# STM32N647xx register map
File version: 1.0
Registers are 32-bit, read-write, reset 0x0 unless marked. A register's access mark holds for its fields unless they carry their own. Offsets are from the block's base; [hi:lo] are bit positions; 'fields as' and 'values as' point back to an identical list.

## DTS — DTS Controller
Base 0x4600A000
0x10 PVTREG_LOCKR — DTS PVT Register Lock Register
  [31:0] LOCK — PVT software lock
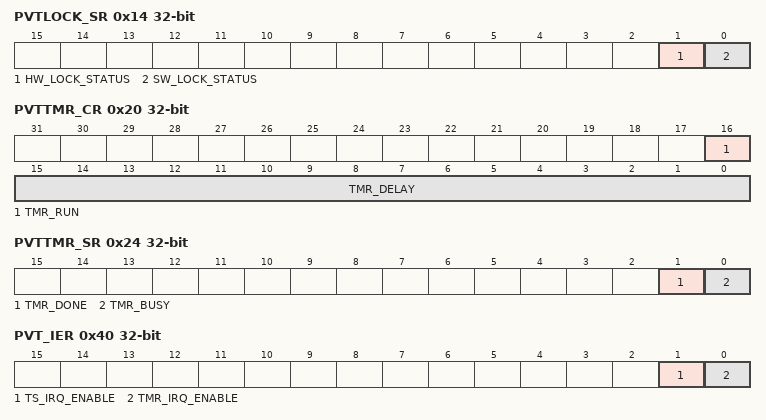
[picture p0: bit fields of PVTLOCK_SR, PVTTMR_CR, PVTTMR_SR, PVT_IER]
0x14 PVTLOCK_SR — DTS PVT Lock Status Register
  [1] HW_LOCK_STATUS — Hardware lock status
  [0] SW_LOCK_STATUS — Software lock status
0x20 PVTTMR_CR — DTS PVT Timer Control Register
  [16] TMR_RUN — Enable
  [15:0] TMR_DELAY — Timer delay
0x24 PVTTMR_SR — DTS PVT Timer Status Register
  [1] TMR_DONE — Cnt delay timeout
  [0] TMR_BUSY — Counter busy flag
0x40 PVT_IER — DTS PVT IRQ Enable Register
  [1] TS_IRQ_ENABLE
  [0] TMR_IRQ_ENABLE — Timer IRQ enable
0x50 PVTIRQTRMASKR — DTS PVT IRQ Timer Mask Register
  [0] TMR_IRQ_MASK — Timer IRQ mask
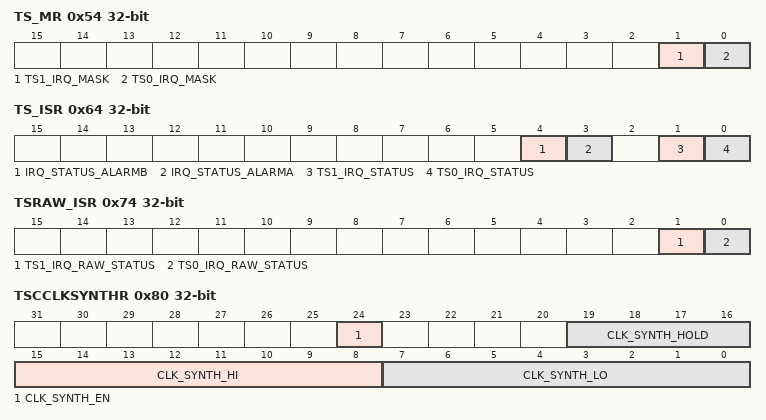
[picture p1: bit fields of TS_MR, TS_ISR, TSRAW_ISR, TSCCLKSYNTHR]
0x54 TS_MR — DTS PVT IRQ TS Mask Register
  [1] TS1_IRQ_MASK, [0] TS0_IRQ_MASK
0x60 PVTTR_SR — DTS PVT IRQ Timer Status Register
  [0] TMR_IRQ_STATUS — Timer IRQ status after masking
0x64 TS_ISR — DTS PVT IRQ TS Status Register
  [4] IRQ_STATUS_ALARMB — TS Alarm B IRQ status
  [3] IRQ_STATUS_ALARMA — TS Alarm A IRQ status
  [1] TS1_IRQ_STATUS — TS1 IRQ status after masking
  [0] TS0_IRQ_STATUS — TS0 IRQ status after masking
0x70 PVTTMRRAW_ISR — DTS PVT IRQ Timer Raw Status Register
  [0] TMR_IRQ_RAW_STATUS — Timer IRQ status before masking
0x74 TSRAW_ISR — DTS PVT IRQ TS Raw Status Register
  [1] TS1_IRQ_RAW_STATUS — TS1 IRQ status before masking
  [0] TS0_IRQ_RAW_STATUS — TS0 IRQ status before masking
0x80 TSCCLKSYNTHR — DTS TSC Clock Synthesizer Register
  [24] CLK_SYNTH_EN — Synthesized enable
  [19:16] CLK_SYNTH_HOLD — Hold input or output delay
  [15:8] CLK_SYNTH_HI — Synthesized clk_ts ghigh period
  [7:0] CLK_SYNTH_LO — Synthesized clk_ts low period
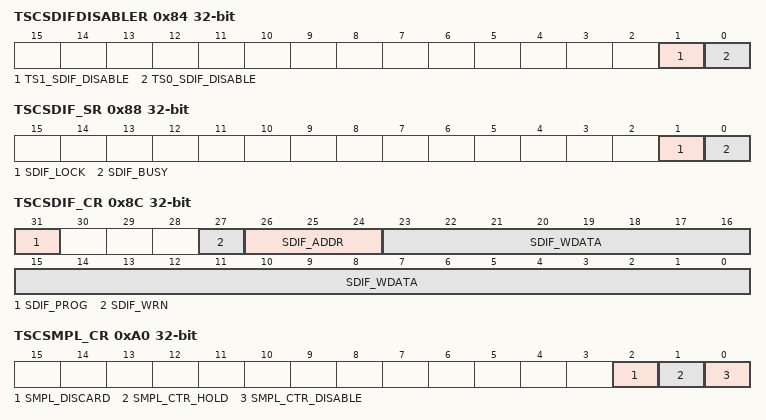
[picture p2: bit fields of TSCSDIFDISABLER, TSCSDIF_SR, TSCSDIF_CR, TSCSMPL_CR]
0x84 TSCSDIFDISABLER — DTS TSC SDIF Interface Disable Register
  [1] TS1_SDIF_DISABLE, [0] TS0_SDIF_DISABLE
0x88 TSCSDIF_SR — DTS TSC SDIF Status Register
  [1] SDIF_LOCK — SDIF locked flag
  [0] SDIF_BUSY — SDIF busy flag
0x8C TSCSDIF_CR — DTS TSC SDIF Register
  [31] SDIF_PROG — SDIF program request
  [27] SDIF_WRN — SDIF write no read control
  [26:24] SDIF_ADDR — SDIF register address
  [23:0] SDIF_WDATA — SDIF write data
0x90 TSCSDIFHALTR — DTS TSC SDIF Halt Register
  [0] SDIF_STOP
0x94 TSCSDIF_CFGR — DTS TSC SDIF Control Register
  [1:0] SDIF_INHIBIT — SDIF programming inhibit
0xA0 TSCSMPL_CR — DTS TSC Sample Control Register
  [2] SMPL_DISCARD — Sample discard
  [1] SMPL_CTR_HOLD — Sample counter hold
  [0] SMPL_CTR_DISABLE — Sample counter disable
0xA4 TSCSDIFSMPLCLRR — DTS TSC Sample Clear Register
  [0] SMPL_CNTER_CLEAR — Sample counter clear
0xA8 TSCSMPLCNTR — DTS TSC Sample Count Register
  [15:0] SMPL_COUNT — Sample counter
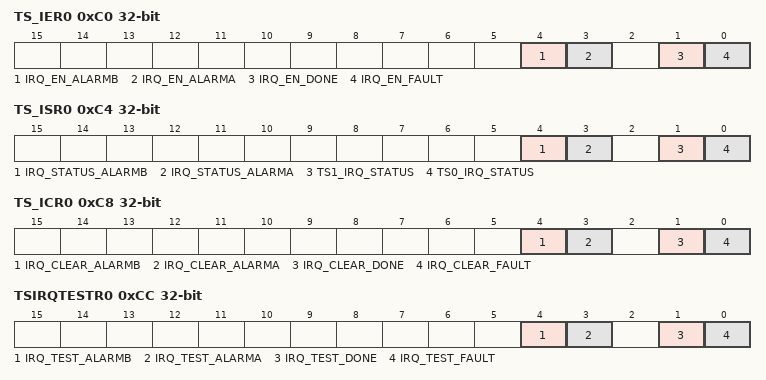
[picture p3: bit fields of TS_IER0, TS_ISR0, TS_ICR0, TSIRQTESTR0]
0xC0 TS_IER0 — DTS TSx IRQ Enable Register
  [4] IRQ_EN_ALARMB — TS Alarm B IRQ enable
  [3] IRQ_EN_ALARMA — TS Alarm A IRQ enable
  [1] IRQ_EN_DONE — TS Sample done IRQ enable
  [0] IRQ_EN_FAULT — TS Fault IRQ enable
0xC4 TS_ISR0 — DTS TSx IRQ Status Register
  fields as TS_ISR
0xC8 TS_ICR0 — DTS TSx IRQ Clear Register
  [4] IRQ_CLEAR_ALARMB — TS Alarm B IRQ clear
  [3] IRQ_CLEAR_ALARMA — TS Alarm A IRQ clear
  [1] IRQ_CLEAR_DONE — TS Sample done IRQ clear
  [0] IRQ_CLEAR_FAULT — TS Fault IRQ clear
0xCC TSIRQTESTR0 — DTS TSx IRQ Test Register
  [4] IRQ_TEST_ALARMB — TS Alarm B IRQ test
  [3] IRQ_TEST_ALARMA — TS Alarm A IRQ test
  [1] IRQ_TEST_DONE — TS Sample done IRQ test
  [0] IRQ_TEST_FAULT — TS Fault IRQ test
0xD0 TSSDIFRDATAR0 — DTS TSx SDIF RDATA Register
  [23:0] SDIF_RDATA — TS SDIF read data
0xD4 TSSDIFDONER0 — DTS TSx SDIF Done Register
  [0] SDIF_SMPL_DONE — TS Sample done flag
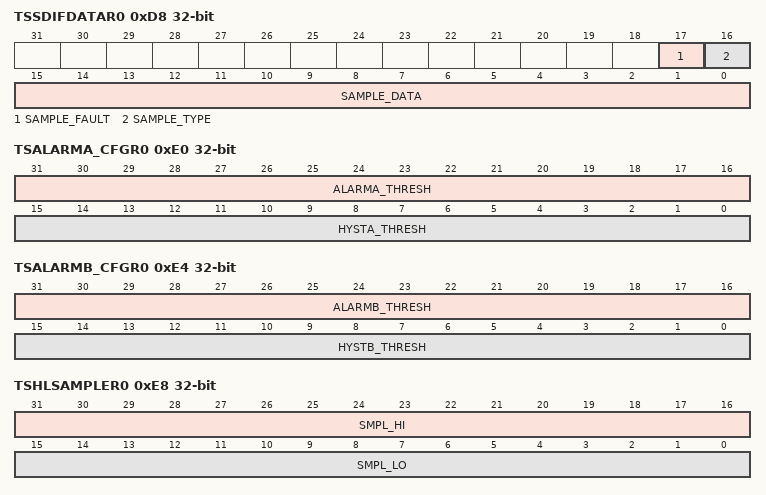
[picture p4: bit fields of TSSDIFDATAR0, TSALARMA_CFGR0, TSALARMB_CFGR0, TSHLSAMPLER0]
0xD8 TSSDIFDATAR0 — DTS TSx SDIF Data Register
  [17] SAMPLE_FAULT — TS Sample fault
  [16] SAMPLE_TYPE — TS Sample type
  [15:0] SAMPLE_DATA — TS Sample data
0xE0 TSALARMA_CFGR0 — DTS TSx Alarm A Configuration Register
  [31:16] ALARMA_THRESH — TS Alarm A threshold
  [15:0] HYSTA_THRESH — TS Alarm A hysteresis threshold
0xE4 TSALARMB_CFGR0 — DTS TSx Alarm B Configuration Register
  [31:16] ALARMB_THRESH — TS Alarm B threshold
  [15:0] HYSTB_THRESH — TS Alarm B hysteresis threshold
0xE8 TSHLSAMPLER0 — DTS TSx High/Low Sample Register
  [31:16] SMPL_HI — TS Highest valid data sample value received
  [15:0] SMPL_LO — TS Lowest valid data sample value received
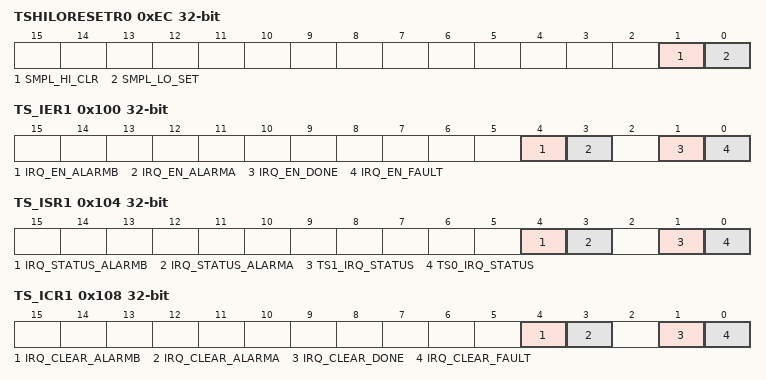
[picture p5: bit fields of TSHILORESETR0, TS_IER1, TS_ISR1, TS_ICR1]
0xEC TSHILORESETR0 — DTS TSx High/Low Reset Register
  [1] SMPL_HI_CLR — TS Sample high clear 0
  [0] SMPL_LO_SET — TS Sample Low Set
0x100 TS_IER1 — DTS TSx IRQ Enable Register
  fields as TS_IER0
0x104 TS_ISR1 — DTS TSx IRQ Status Register
  fields as TS_ISR
0x108 TS_ICR1 — DTS TSx IRQ Clear Register
  fields as TS_ICR0
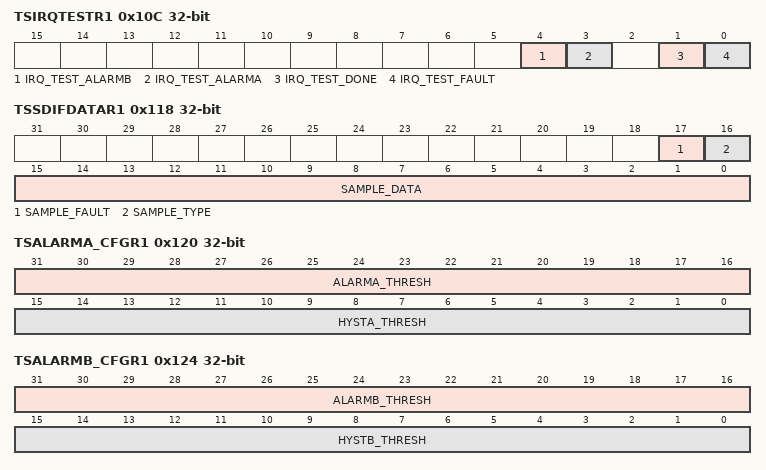
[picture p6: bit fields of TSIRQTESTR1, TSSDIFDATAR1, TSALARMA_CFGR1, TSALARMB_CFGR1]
0x10C TSIRQTESTR1 — DTS TSx IRQ Test Register
  fields as TSIRQTESTR0
0x110 TSSDIFRDATAR1 — DTS TSx SDIF RDATA Register
  [23:0] SDIF_RDATA — TS SDIF read data
0x114 TSSDIFDONER1 — DTS TSx SDIF Done Register
  [0] SDIF_SMPL_DONE — TS Sample done flag
0x118 TSSDIFDATAR1 — DTS TSx SDIF Data Register
  fields as TSSDIFDATAR0
0x120 TSALARMA_CFGR1 — DTS TSx Alarm A Configuration Register
  fields as TSALARMA_CFGR0
0x124 TSALARMB_CFGR1 — DTS TSx Alarm B Configuration Register
  fields as TSALARMB_CFGR0
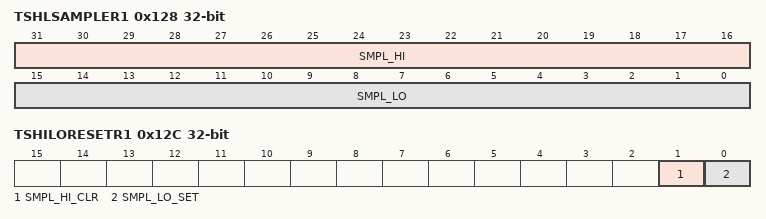
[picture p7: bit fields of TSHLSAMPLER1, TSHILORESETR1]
0x128 TSHLSAMPLER1 — DTS TSx High/Low Sample Register
  fields as TSHLSAMPLER0
0x12C TSHILORESETR1 — DTS TSx High/Low Reset Register
  fields as TSHILORESETR0
